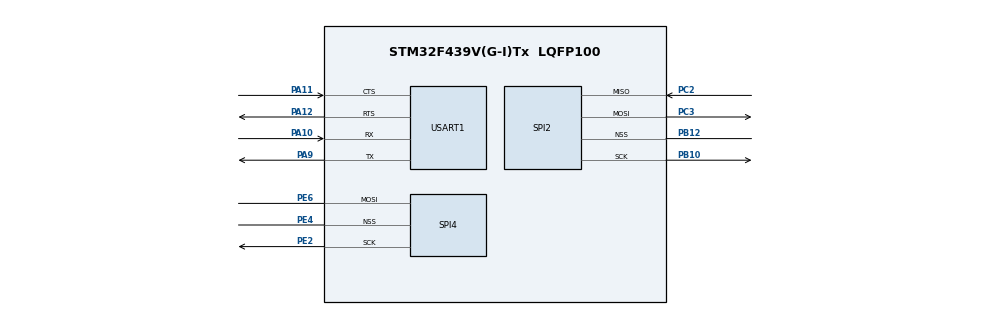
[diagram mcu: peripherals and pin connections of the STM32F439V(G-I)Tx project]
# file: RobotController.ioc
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Mcu.Family=STM32F4
Mcu.Name=STM32F439V(G-I)Tx
Mcu.Package=LQFP100
NVIC.PriorityGroup=NVIC_PRIORITYGROUP_0
PA10.Mode=Asynchronous
PA10.Signal=USART1_RX
PA11.Mode=CTS_RTS
PA11.Signal=USART1_CTS
PA12.Mode=CTS_RTS
PA12.Signal=USART1_RTS
PA9.Mode=Asynchronous
PA9.Signal=USART1_TX
PB10.Mode=Full_Duplex_Master
PB10.Signal=SPI2_SCK
PB12.Mode=NSS_Signal_Hard
PB12.Signal=SPI2_NSS
PC2.Mode=Full_Duplex_Master
PC2.Signal=SPI2_MISO
PC3.Mode=Full_Duplex_Master
PC3.Signal=SPI2_MOSI
PE2.Mode=Simplex_Bidirectional_Master
PE2.Signal=SPI4_SCK
PE4.Mode=NSS_Signal_Hard
PE4.Signal=SPI4_NSS
PE6.Mode=Simplex_Bidirectional_Master
PE6.Signal=SPI4_MOSI
ProjectManager.TargetToolchain=MDK-ARM 4.73
RCC.HSE_VALUE=25000000
RCC.HSI_VALUE=16000000
RCC.LSE_VALUE=32768
SPI2.CalculateBaudRate-Full_Duplex_Master=8.0 MBits/s
SPI2.Mode-Full_Duplex_Master=SPI_MODE_MASTER
SPI2.VirtualNSS=VM_NSSHARD
SPI4.CalculateBaudRate-Simplex_Bidirectional_Master=8.0 MBits/s
SPI4.Direction-Simplex_Bidirectional_Master=SPI_DIRECTION_1LINE
SPI4.Mode-Simplex_Bidirectional_Master=SPI_MODE_MASTER
SPI4.VirtualNSS=VM_NSSHARD
VP_RTC_VS_RTC_WakeUp_intern.Mode=WakeUp

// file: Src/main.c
/**
  ******************************************************************************
  * File Name          : main.c
  * Date               : 10/06/2014 20:34:25
  * Description        : Main program body
  ******************************************************************************
  *
  * COPYRIGHT(c) 2014 STMicroelectronics
  *
  * Redistribution and use in source and binary forms, with or without modification,
  * are permitted provided that the following conditions are met:
  *   1. Redistributions of source code must retain the above copyright notice,
  *      this list of conditions and the following disclaimer.
  *   2. Redistributions in binary form must reproduce the above copyright notice,
  *      this list of conditions and the following disclaimer in the documentation
  *      and/or other materials provided with the distribution.
  *   3. Neither the name of STMicroelectronics nor the names of its contributors
  *      may be used to endorse or promote products derived from this software
  *      without specific prior written permission.
  *
  * THIS SOFTWARE IS PROVIDED BY THE COPYRIGHT HOLDERS AND CONTRIBUTORS "AS IS"
  * AND ANY EXPRESS OR IMPLIED WARRANTIES, INCLUDING, BUT NOT LIMITED TO, THE
  * IMPLIED WARRANTIES OF MERCHANTABILITY AND FITNESS FOR A PARTICULAR PURPOSE ARE
  * DISCLAIMED. IN NO EVENT SHALL THE COPYRIGHT HOLDER OR CONTRIBUTORS BE LIABLE
  * FOR ANY DIRECT, INDIRECT, INCIDENTAL, SPECIAL, EXEMPLARY, OR CONSEQUENTIAL
  * DAMAGES (INCLUDING, BUT NOT LIMITED TO, PROCUREMENT OF SUBSTITUTE GOODS OR
  * SERVICES; LOSS OF USE, DATA, OR PROFITS; OR BUSINESS INTERRUPTION) HOWEVER
  * CAUSED AND ON ANY THEORY OF LIABILITY, WHETHER IN CONTRACT, STRICT LIABILITY,
  * OR TORT (INCLUDING NEGLIGENCE OR OTHERWISE) ARISING IN ANY WAY OUT OF THE USE
  * OF THIS SOFTWARE, EVEN IF ADVISED OF THE POSSIBILITY OF SUCH DAMAGE.
  *
  ******************************************************************************
  */

#include "stm32f4xx_hal.h"

RTC_HandleTypeDef hrtc;

SPI_HandleTypeDef hspi2;
SPI_HandleTypeDef hspi4;

UART_HandleTypeDef huart1;

static void SystemClock_Config(void);
static void MX_GPIO_Init(void);
static void MX_RTC_Init(void);
static void MX_SPI2_Init(void);
static void MX_SPI4_Init(void);
static void MX_USART1_UART_Init(void);

int main(void)
{

  /* MCU Configuration----------------------------------------------------------*/

  /* Reset of all peripherals, Initializes the Flash interface and the Systick. */
  HAL_Init();

  /* Configure the system clock */
  SystemClock_Config();

  /* Initialize all configured peripherals */
  MX_GPIO_Init();
  MX_RTC_Init();
  MX_SPI2_Init();
  MX_SPI4_Init();
  MX_USART1_UART_Init();

  /* USER CODE BEGIN 3 */
  /* Infinite loop */

	//set low level to ground
	HAL_GPIO_WritePin(GPIOC,GPIO_PIN_1 | GPIO_PIN_3, GPIO_PIN_SET);

	uint8_t string[] = "Hello world!\n";

  while (1)
  {
		HAL_UART_Transmit(&huart1, string, 12, 100);
		HAL_GPIO_TogglePin(GPIOA,GPIO_PIN_1 | GPIO_PIN_5);
		for (int i = 0; i < 5000000; i++);
  }
  /* USER CODE END 3 */

}

/** System Clock Configuration
*/
static void SystemClock_Config(void)
{

  RCC_PeriphCLKInitTypeDef PeriphClkInitStruct;
  RCC_OscInitTypeDef RCC_OscInitStruct;

  __PWR_CLK_ENABLE();

  __HAL_PWR_VOLTAGESCALING_CONFIG(PWR_REGULATOR_VOLTAGE_SCALE3);

  RCC_OscInitStruct.OscillatorType = RCC_OSCILLATORTYPE_HSI|RCC_OSCILLATORTYPE_LSI;
  RCC_OscInitStruct.HSIState = RCC_HSI_ON;
  RCC_OscInitStruct.HSICalibrationValue = 6;
  RCC_OscInitStruct.LSIState = RCC_LSI_ON;
  HAL_RCC_OscConfig(&RCC_OscInitStruct);

  PeriphClkInitStruct.PeriphClockSelection = RCC_PERIPHCLK_RTC;
  PeriphClkInitStruct.RTCClockSelection = RCC_RTCCLKSOURCE_LSI;
  HAL_RCCEx_PeriphCLKConfig(&PeriphClkInitStruct);

}

/* RTC init function */
void MX_RTC_Init(void)
{

  RTC_TimeTypeDef sTime;
  RTC_DateTypeDef sDate;

    /**Initialize RTC and set the Time and Date
    */
  hrtc.Instance = RTC;
  hrtc.Init.HourFormat = RTC_HOURFORMAT_24;
  hrtc.Init.AsynchPrediv = 127;
  hrtc.Init.SynchPrediv = 255;
  hrtc.Init.OutPut = RTC_OUTPUT_DISABLE;
  hrtc.Init.OutPutPolarity = RTC_OUTPUT_POLARITY_HIGH;
  hrtc.Init.OutPutType = RTC_OUTPUT_TYPE_OPENDRAIN;
  HAL_RTC_Init(&hrtc);

  sTime.Hours = 0;
  sTime.Minutes = 0;
  sTime.Seconds = 0;
  sTime.SubSeconds = 0;
  sTime.TimeFormat = RTC_HOURFORMAT12_AM;
  sTime.DayLightSaving = RTC_DAYLIGHTSAVING_SUB1H;
  sTime.StoreOperation = RTC_STOREOPERATION_RESET;
  HAL_RTC_SetTime(&hrtc, &sTime, FORMAT_BCD);

  sDate.WeekDay = RTC_WEEKDAY_MONDAY;
  sDate.Month = RTC_MONTH_JANUARY;
  sDate.Date = 1;
  sDate.Year = 0;
  HAL_RTC_SetDate(&hrtc, &sDate, FORMAT_BCD);

    /**Enable the WakeUp
    */
  HAL_RTCEx_SetWakeUpTimer(&hrtc, 0, RTC_WAKEUPCLOCK_RTCCLK_DIV16);

}

/* SPI2 init function */
void MX_SPI2_Init(void)
{

  hspi2.Instance = SPI2;
  hspi2.Init.Mode = SPI_MODE_MASTER;
  hspi2.Init.Direction = SPI_DIRECTION_2LINES;
  hspi2.Init.DataSize = SPI_DATASIZE_8BIT;
  hspi2.Init.CLKPolarity = SPI_POLARITY_LOW;
  hspi2.Init.CLKPhase = SPI_PHASE_1EDGE;
  hspi2.Init.NSS = SPI_NSS_HARD_OUTPUT;
  hspi2.Init.BaudRatePrescaler = SPI_BAUDRATEPRESCALER_2;
  hspi2.Init.FirstBit = SPI_FIRSTBIT_MSB;
  hspi2.Init.TIMode = SPI_TIMODE_DISABLED;
  hspi2.Init.CRCCalculation = SPI_CRCCALCULATION_DISABLED;
  HAL_SPI_Init(&hspi2);

}

/* SPI4 init function */
void MX_SPI4_Init(void)
{

  hspi4.Instance = SPI4;
  hspi4.Init.Mode = SPI_MODE_MASTER;
  hspi4.Init.Direction = SPI_DIRECTION_1LINE;
  hspi4.Init.DataSize = SPI_DATASIZE_8BIT;
  hspi4.Init.CLKPolarity = SPI_POLARITY_LOW;
  hspi4.Init.CLKPhase = SPI_PHASE_1EDGE;
  hspi4.Init.NSS = SPI_NSS_HARD_OUTPUT;
  hspi4.Init.BaudRatePrescaler = SPI_BAUDRATEPRESCALER_2;
  hspi4.Init.FirstBit = SPI_FIRSTBIT_MSB;
  hspi4.Init.TIMode = SPI_TIMODE_DISABLED;
  hspi4.Init.CRCCalculation = SPI_CRCCALCULATION_DISABLED;
  HAL_SPI_Init(&hspi4);

}

/* USART1 init function */
void MX_USART1_UART_Init(void)
{

  huart1.Instance = USART1;
  huart1.Init.BaudRate = 115200;
  huart1.Init.WordLength = UART_WORDLENGTH_8B;
  huart1.Init.StopBits = UART_STOPBITS_1;
  huart1.Init.Parity = UART_PARITY_NONE;
  huart1.Init.Mode = UART_MODE_TX_RX;
  huart1.Init.HwFlowCtl = UART_HWCONTROL_RTS_CTS;
  huart1.Init.OverSampling = UART_OVERSAMPLING_16;
  HAL_UART_Init(&huart1);

}

/** Pinout Configuration
*/
void MX_GPIO_Init(void)
{

  /* GPIO Ports Clock Enable */
  __GPIOE_CLK_ENABLE();
  __GPIOC_CLK_ENABLE();
  __GPIOB_CLK_ENABLE();
  __GPIOA_CLK_ENABLE();

}

/************************ (C) COPYRIGHT STMicroelectronics *****END OF FILE****/
